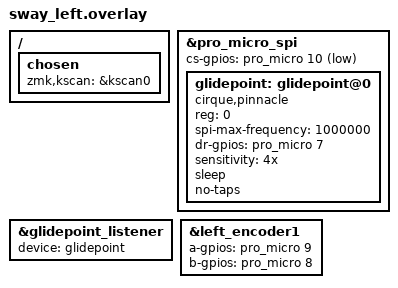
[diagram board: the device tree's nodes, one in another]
/*
 * Copyright (c) 2022 The ZMK Contributors
 *
 * SPDX-License-Identifier: MIT
 */

#include <dt-bindings/zmk/input_transform.h>
#include "sway.dtsi"

/ {
    chosen {
        zmk,kscan = &kscan0;
    };
};

&pro_micro_spi {
    status = "okay";
    cs-gpios = <&pro_micro 10 GPIO_ACTIVE_LOW>;

    glidepoint: glidepoint@0 {
        compatible = "cirque,pinnacle";
        reg = <0>;
        spi-max-frequency = <1000000>;
        status = "okay";
        dr-gpios = <&pro_micro 7 (GPIO_ACTIVE_HIGH)>;

        sensitivity = "4x";
        sleep;
        no-taps;
    };
};

// Overrides for the input listener node
&glidepoint_listener {
    status = "okay";
    device = <&glidepoint>;
};

&left_encoder1 {
    status = "okay";
    a-gpios = <&pro_micro 9 GPIO_PULL_UP>;
    b-gpios = <&pro_micro 8 GPIO_PULL_UP>;
};
